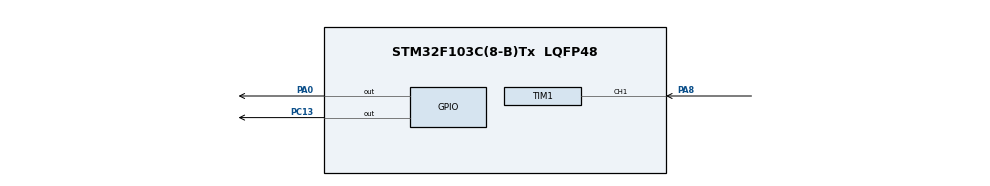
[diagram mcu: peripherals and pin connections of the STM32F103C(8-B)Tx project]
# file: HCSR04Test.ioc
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Mcu.Family=STM32F1
Mcu.Name=STM32F103C(8-B)Tx
Mcu.Package=LQFP48
NVIC.PriorityGroup=NVIC_PRIORITYGROUP_4
PA0-WKUP.Signal=GPIO_Output
PA13.Mode=Serial_Wire
PA13.Signal=SYS_JTMS-SWDIO
PA14.Mode=Serial_Wire
PA14.Signal=SYS_JTCK-SWCLK
PA8.Signal=S_TIM1_CH1
PC13-TAMPER-RTC.GPIO_ModeDefaultOutputPP=GPIO_MODE_OUTPUT_OD
PC13-TAMPER-RTC.GPIO_PuPd=GPIO_NOPULL
PC13-TAMPER-RTC.PinState=GPIO_PIN_SET
PC13-TAMPER-RTC.Signal=GPIO_Output
ProjectManager.HeapSize=0x200
ProjectManager.StackSize=0x400
ProjectManager.TargetToolchain=MDK-ARM V5.32
RCC.APB1Freq_Value=8000000
RCC.APB2Freq_Value=8000000
SH.S_TIM1_CH1.0=TIM1_CH1,Input_Capture1_from_TI1
TIM1.AutoReloadPreload=TIM_AUTORELOAD_PRELOAD_ENABLE
TIM1.Channel-Input_Capture1_from_TI1=TIM_CHANNEL_1
TIM1.Channel-Input_Capture2_from_TI1_63=TIM_CHANNEL_2
TIM1.ICPolarity_CH2=TIM_INPUTCHANNELPOLARITY_FALLING
TIM1.Prescaler=7
VP_TIM1_VS_ClockSourceINT.Mode=Internal
VP_TIM1_VS_indirect_ch1.Mode=Input_Capture2_from_TI1_63
board=custom

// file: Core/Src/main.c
/* USER CODE BEGIN Header */
/**
  ******************************************************************************
  * @file           : main.c
  * @brief          : Main program body
  ******************************************************************************
  * @attention
  *
  * Copyright (c) 2026 STMicroelectronics.
  * All rights reserved.
  *
  * This software is licensed under terms that can be found in the LICENSE file
  * in the root directory of this software component.
  * If no LICENSE file comes with this software, it is provided AS-IS.
  *
  ******************************************************************************
  */
/* USER CODE END Header */
#include "main.h"

TIM_HandleTypeDef htim1;

void SystemClock_Config(void);
static void MX_GPIO_Init(void);
static void MX_TIM1_Init(void);

int main(void)
{

  /* MCU Configuration--------------------------------------------------------*/

  /* Reset of all peripherals, Initializes the Flash interface and the Systick. */
  HAL_Init();

  /* Configure the system clock */
  SystemClock_Config();

  /* Initialize all configured peripherals */
  MX_GPIO_Init();
  MX_TIM1_Init();

  /* Infinite loop */
  /* USER CODE BEGIN WHILE */
  while (1)
  {
		// 1. 让计数器归零
		__HAL_TIM_SET_COUNTER (&htim1 ,0);

		// 2.清除cc1和cc2标志位
		__HAL_TIM_CLEAR_FLAG (&htim1 ,TIM_FLAG_CC1 );
		__HAL_TIM_CLEAR_FLAG (&htim1 ,TIM_FLAG_CC2 );

		// 3.启动输入捕获//同时能打开时基单元开关
		HAL_TIM_IC_Start (&htim1 ,TIM_CHANNEL_1 );
		HAL_TIM_IC_Start (&htim1 ,TIM_CHANNEL_2 );

		// 4.向trig引脚发送脉冲
		HAL_GPIO_WritePin (GPIOA ,GPIO_PIN_0 ,GPIO_PIN_SET );

	  for(uint32_t i=0;i<10;i++);

		HAL_GPIO_WritePin (GPIOA ,GPIO_PIN_0 ,GPIO_PIN_RESET) ;

		// 5.等待测量结束
		uint32_t expireTime=HAL_GetTick ()+50;
		uint8_t success=0;
		while(expireTime>HAL_GetTick ())
		{
		 uint32_t cc1flag=__HAL_TIM_GET_FLAG (&htim1 ,TIM_FLAG_CC1 );
		 uint32_t cc2flag=__HAL_TIM_GET_FLAG (&htim1 ,TIM_FLAG_CC2 );

			if(cc1flag&&cc2flag)
			{
				success =1;
				break ;
			}
		}

		// 6.关闭定时器
		HAL_TIM_IC_Stop (&htim1 ,TIM_CHANNEL_1 );
		HAL_TIM_IC_Stop (&htim1 ,TIM_CHANNEL_2 );

		// 7.计算
		if(success ==1)
		{
			uint16_t ccr1=__HAL_TIM_GET_COMPARE (&htim1 ,TIM_CHANNEL_1 );
			uint16_t ccr2=__HAL_TIM_GET_COMPARE (&htim1 ,TIM_CHANNEL_2 );

			float pulseWidth=(ccr2-ccr1)*1e-6f;
			float distance= 340.0f*pulseWidth /2.0f;

			if(distance <0.2)
			{
				HAL_GPIO_WritePin (GPIOC,GPIO_PIN_13 ,GPIO_PIN_RESET );
			}
			else
			{
				HAL_GPIO_WritePin (GPIOC,GPIO_PIN_13 ,GPIO_PIN_SET );
			}
		}

    /* USER CODE END WHILE */

  }
}

void SystemClock_Config(void)
{
  RCC_OscInitTypeDef RCC_OscInitStruct = {0};
  RCC_ClkInitTypeDef RCC_ClkInitStruct = {0};

  /** Initializes the RCC Oscillators according to the specified parameters
  * in the RCC_OscInitTypeDef structure.
  */
  RCC_OscInitStruct.OscillatorType = RCC_OSCILLATORTYPE_HSI;
  RCC_OscInitStruct.HSIState = RCC_HSI_ON;
  RCC_OscInitStruct.HSICalibrationValue = RCC_HSICALIBRATION_DEFAULT;
  RCC_OscInitStruct.PLL.PLLState = RCC_PLL_NONE;
  if (HAL_RCC_OscConfig(&RCC_OscInitStruct) != HAL_OK)
  {
    Error_Handler();
  }

  /** Initializes the CPU, AHB and APB buses clocks
  */
  RCC_ClkInitStruct.ClockType = RCC_CLOCKTYPE_HCLK|RCC_CLOCKTYPE_SYSCLK
                              |RCC_CLOCKTYPE_PCLK1|RCC_CLOCKTYPE_PCLK2;
  RCC_ClkInitStruct.SYSCLKSource = RCC_SYSCLKSOURCE_HSI;
  RCC_ClkInitStruct.AHBCLKDivider = RCC_SYSCLK_DIV1;
  RCC_ClkInitStruct.APB1CLKDivider = RCC_HCLK_DIV1;
  RCC_ClkInitStruct.APB2CLKDivider = RCC_HCLK_DIV1;

  if (HAL_RCC_ClockConfig(&RCC_ClkInitStruct, FLASH_LATENCY_0) != HAL_OK)
  {
    Error_Handler();
  }
}

static void MX_TIM1_Init(void)
{

  TIM_ClockConfigTypeDef sClockSourceConfig = {0};
  TIM_MasterConfigTypeDef sMasterConfig = {0};
  TIM_IC_InitTypeDef sConfigIC = {0};

  htim1.Instance = TIM1;
  htim1.Init.Prescaler = 7;
  htim1.Init.CounterMode = TIM_COUNTERMODE_UP;
  htim1.Init.Period = 65535;
  htim1.Init.ClockDivision = TIM_CLOCKDIVISION_DIV1;
  htim1.Init.RepetitionCounter = 0;
  htim1.Init.AutoReloadPreload = TIM_AUTORELOAD_PRELOAD_ENABLE;
  if (HAL_TIM_Base_Init(&htim1) != HAL_OK)
  {
    Error_Handler();
  }
  sClockSourceConfig.ClockSource = TIM_CLOCKSOURCE_INTERNAL;
  if (HAL_TIM_ConfigClockSource(&htim1, &sClockSourceConfig) != HAL_OK)
  {
    Error_Handler();
  }
  if (HAL_TIM_IC_Init(&htim1) != HAL_OK)
  {
    Error_Handler();
  }
  sMasterConfig.MasterOutputTrigger = TIM_TRGO_RESET;
  sMasterConfig.MasterSlaveMode = TIM_MASTERSLAVEMODE_DISABLE;
  if (HAL_TIMEx_MasterConfigSynchronization(&htim1, &sMasterConfig) != HAL_OK)
  {
    Error_Handler();
  }
  sConfigIC.ICPolarity = TIM_INPUTCHANNELPOLARITY_RISING;
  sConfigIC.ICSelection = TIM_ICSELECTION_DIRECTTI;
  sConfigIC.ICPrescaler = TIM_ICPSC_DIV1;
  sConfigIC.ICFilter = 0;
  if (HAL_TIM_IC_ConfigChannel(&htim1, &sConfigIC, TIM_CHANNEL_1) != HAL_OK)
  {
    Error_Handler();
  }
  sConfigIC.ICPolarity = TIM_INPUTCHANNELPOLARITY_FALLING;
  sConfigIC.ICSelection = TIM_ICSELECTION_INDIRECTTI;
  if (HAL_TIM_IC_ConfigChannel(&htim1, &sConfigIC, TIM_CHANNEL_2) != HAL_OK)
  {
    Error_Handler();
  }

}

static void MX_GPIO_Init(void)
{
  GPIO_InitTypeDef GPIO_InitStruct = {0};

  /* GPIO Ports Clock Enable */
  __HAL_RCC_GPIOC_CLK_ENABLE();
  __HAL_RCC_GPIOA_CLK_ENABLE();

  /*Configure GPIO pin Output Level */
  HAL_GPIO_WritePin(GPIOC, GPIO_PIN_13, GPIO_PIN_SET);

  /*Configure GPIO pin Output Level */
  HAL_GPIO_WritePin(GPIOA, GPIO_PIN_0, GPIO_PIN_RESET);

  /*Configure GPIO pin : PC13 */
  GPIO_InitStruct.Pin = GPIO_PIN_13;
  GPIO_InitStruct.Mode = GPIO_MODE_OUTPUT_OD;
  GPIO_InitStruct.Pull = GPIO_NOPULL;
  GPIO_InitStruct.Speed = GPIO_SPEED_FREQ_LOW;
  HAL_GPIO_Init(GPIOC, &GPIO_InitStruct);

  /*Configure GPIO pin : PA0 */
  GPIO_InitStruct.Pin = GPIO_PIN_0;
  GPIO_InitStruct.Mode = GPIO_MODE_OUTPUT_PP;
  GPIO_InitStruct.Pull = GPIO_NOPULL;
  GPIO_InitStruct.Speed = GPIO_SPEED_FREQ_LOW;
  HAL_GPIO_Init(GPIOA, &GPIO_InitStruct);

}

void Error_Handler(void)
{
  __disable_irq();
  while (1)
  {
  }
}
